# PIC32CX5109BZ31048 device description
Architecture: CORTEX-M4; Family: PIC32CX; Series: PIC32CXBZ31
Registers are 32-bit, read-write, reset 0x0 unless marked. A register's access mark holds for its fields unless they carry their own. Offsets are from the block's base; [hi:lo] are bit positions; lines under a group give offsets from that group; {n}, {i} and the like mark numbered series.

## GPIO
Instances: GPIOA 0x44002A00, GPIOB 0x44002B00
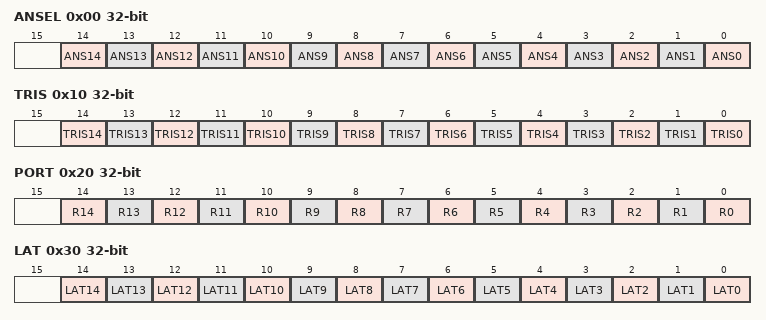
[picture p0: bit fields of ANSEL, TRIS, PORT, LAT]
0x00 ANSEL
  [n] ANS{n} (n=0..14)
0x04 ANSELCLR
0x08 ANSELSET
0x0C ANSELINV
0x10 TRIS
  [n] TRIS{n} (n=0..14)
0x14 TRISCLR
0x18 TRISSET
0x1C TRISINV
0x20 PORT
  [n] R{n} (n=0..14)
0x24 PORTCLR
0x28 PORTSET
0x2C PORTINV
0x30 LAT
  [n] LAT{n} (n=0..14)
0x34 LATCLR
0x38 LATSET
0x3C LATINV
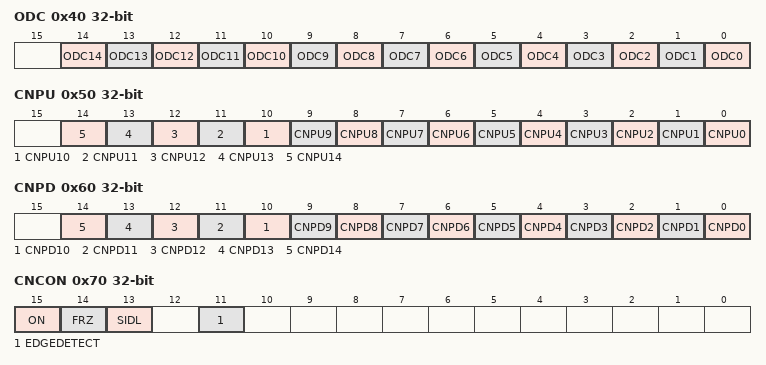
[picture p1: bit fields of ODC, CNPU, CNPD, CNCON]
0x40 ODC
  [n] ODC{n} (n=0..14)
0x44 ODCCLR
0x48 ODCSET
0x4C ODCINV
0x50 CNPU
  [n] CNPU{n} (n=0..14)
0x54 CNPUCLR
0x58 CNPUSET
0x5C CNPUINV
0x60 CNPD
  [n] CNPD{n} (n=0..14)
0x64 CNPDCLR
0x68 CNPDSET
0x6C CNPDINV
0x70 CNCON
  [15] ON, [14] FRZ, [13] SIDL, [11] EDGEDETECT
0x74 CNCONCLR
0x78 CNCONSET
0x7C CNCONINV
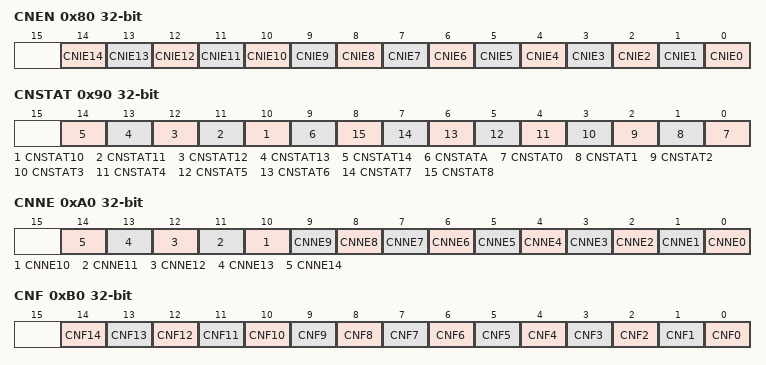
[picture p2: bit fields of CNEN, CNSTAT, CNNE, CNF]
0x80 CNEN
  [n] CNIE{n} (n=0..14)
0x84 CNENCLR
0x88 CNENSET
0x8C CNENINV
0x90 CNSTAT
  [n] CNSTAT{n} (n=10..14), [9] CNSTATA, [n] CNSTAT{n} (n=0..8)
0x94 CNSTATCLR
0x98 CNSTATSET
0x9C CNSTATINV
0xA0 CNNE
  [n] CNNE{n} (n=0..14)
0xA4 CNNECLR
0xA8 CNNESET
0xAC CNNEINV
0xB0 CNF
  [n] CNF{n} (n=0..14)
0xB4 CNFCLR
0xB8 CNFSET
0xBC CNFINV
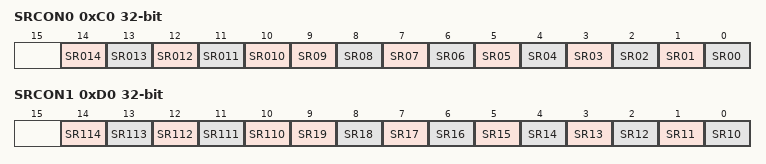
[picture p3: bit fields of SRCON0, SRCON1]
0xC0 SRCON0
  [n] SR{n:03} (n=10..14), [n] SR{n:02} (n=0..9)
0xC4 SRCON0CLR
0xC8 SRCON0SET
0xCC SRCON0INV
0xD0 SRCON1
  [n-100] SR{n} (n=110..114), [n-10] SR{n} (n=10..19)
0xD4 SRCON1CLR
0xD8 SRCON1SET
0xDC SRCON1INV

## HMATRIX2TOP — HSB Matrix
Instances: HMATRIX2TOP 0x42002400
{0x80+8i} PRS[{i}] (i=0..15) group
  0x00 PRAS — Priority A for Slave
  0x04 PRBS — Priority B for Slave

## PAC — Peripheral Access Controller
Instances: PAC 0x40000000
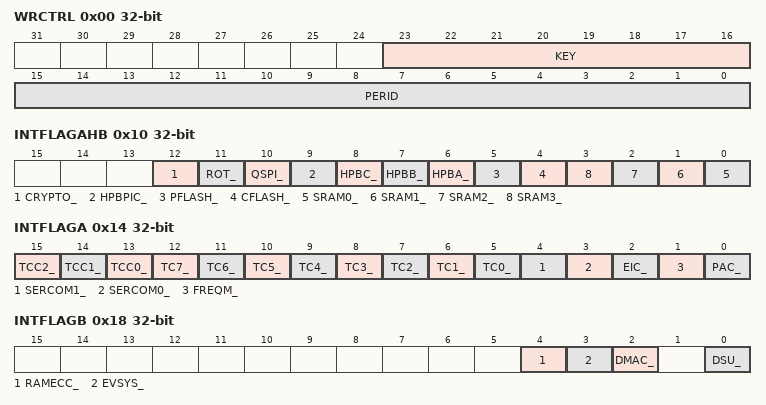
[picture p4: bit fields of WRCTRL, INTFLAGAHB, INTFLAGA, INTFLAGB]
0x00 WRCTRL — Write control
  [23:16] KEY — Peripheral access control key
    0=OFF (No action); 1=CLR (Clear protection); 2=SET (Set protection); 3=SETLCK (Set and lock protection)
  [15:0] PERID — Peripheral identifier
0x04 EVCTRL 8-bit — Event control
  [0] ERREO — Peripheral acess error event output
0x08 INTENCLR 8-bit (atomic clear) — Interrupt enable clear
  [0] ERR — Peripheral access error interrupt disable
0x09 INTENSET 8-bit (atomic set) — Interrupt enable set
  [0] ERR — Peripheral access error interrupt enable
0x10 INTFLAGAHB (atomic clear) — Bridge interrupt flag status
  [12] CRYPTO_
  [11] ROT_
  [10] QSPI_
  [9] HPBPIC_ — HPBPIC0
  [8] HPBC_
  [7] HPBB_
  [6] HPBA_
  [5] PFLASH_
  [4] CFLASH_
  [n] SRAM{n}_ (n=0..3)
0x14 INTFLAGA (atomic clear) — Peripheral interrupt flag status - Bridge A
  [15] TCC2_, [14] TCC1_, [13] TCC0_, [n+5] TC{n}_ (n=0..7), [4] SERCOM1_, [3] SERCOM0_, [2] EIC_, [1] FREQM_, [0] PAC_
0x18 INTFLAGB (atomic clear) — Peripheral interrupt flag status - Bridge B
  [4] RAMECC_, [3] EVSYS_, [2] DMAC_, [0] DSU_
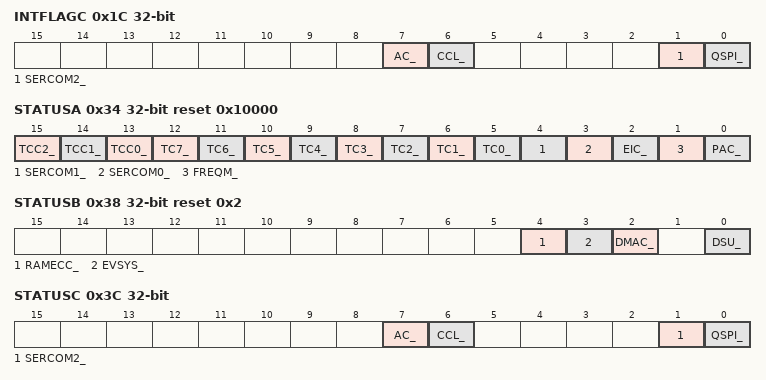
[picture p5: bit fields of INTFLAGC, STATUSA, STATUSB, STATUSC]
0x1C INTFLAGC (atomic clear) — Peripheral interrupt flag status - Bridge C
  [7] AC_, [6] CCL_, [1] SERCOM2_, [0] QSPI_
0x34 STATUSA ro reset 0x10000 — Peripheral write protection status - Bridge A
  [15] TCC2_ — TCC2 APB Protect Enable
  [14] TCC1_ — TCC1 APB Protect Enable
  [13] TCC0_ — TCC0 APB Protect Enable
  [n+5] TC{n}_ (n=0..7) — TC{n} APB Protect Enable
  [4] SERCOM1_ — SERCOM1 APB Protect Enable
  [3] SERCOM0_ — SERCOM0 APB Protect Enable
  [2] EIC_ — EIC APB Protect Enable
  [1] FREQM_ — FREQM APB Protect Enable
  [0] PAC_ — PAC APB Protect Enable
0x38 STATUSB ro reset 0x2 — Peripheral write protection status - Bridge B
  [4] RAMECC_ — RAMECC APB Protect Enable
  [3] EVSYS_ — EVSYS APB Protect Enable
  [2] DMAC_ — DMAC APB Protect Enable
  [0] DSU_ — DSU APB Protect Enable
0x3C STATUSC ro — Peripheral write protection status - Bridge C
  [7] AC_ — AC APB Protect Enable
  [6] CCL_ — CCL APB Protect Enable
  [1] SERCOM2_ — SERCOM2 APB Protect Enable
  [0] QSPI_ — QSPI APB Protect Enable

## PCHE — this is the PCHE
Instances: PCHE 0x44012400
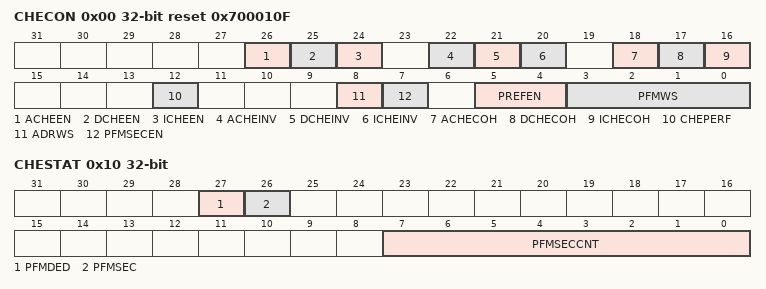
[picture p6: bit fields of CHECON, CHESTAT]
0x00 CHECON reset 0x700010F
  [26] ACHEEN, [25] DCHEEN, [24] ICHEEN, [22] ACHEINV, [21] DCHEINV, [20] ICHEINV, [18] ACHECOH, [17] DCHECOH, [16] ICHECOH, [12] CHEPERF, [8] ADRWS, [7] PFMSECEN, [5:4] PREFEN, [3:0] PFMWS
0x04 CHECONCLR
0x08 CHECONSET
0x0C CHECONINV
0x10 CHESTAT
  [27] PFMDED, [26] PFMSEC, [7:0] PFMSECCNT
0x14 CHESTATCLR
0x18 CHESTATSET
0x1C CHESTATINV
0x20 CHEHIT
0x24 CHEHITCLR
0x28 CHEHITSET
0x2C CHEHITINV
0x30 CHEMIS
0x34 CHEMISCLR
0x38 CHEMISSET
0x3C CHEMISINV

## Notices in the file
Copyright (c) 2021 Microchip Technology Inc.
SPDX-License-Identifier: Apache-2.0
Licensed under the Apache License, Version 2.0 (the "License");
you may not use this file except in compliance with the License.
You may obtain a copy of the License at
http://www.apache.org/licenses/LICENSE-2.0
Unless required by applicable law or agreed to in writing, software
distributed under the License is distributed on an "AS IS" BASIS,
WITHOUT WARRANTIES OR CONDITIONS OF ANY KIND, either express or implied.
See the License for the specific language governing permissions and
limitations under the License.
